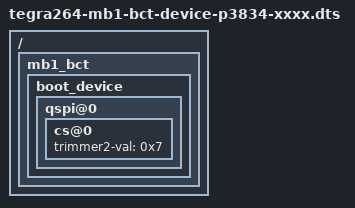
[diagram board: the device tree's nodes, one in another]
/*
 * SPDX-FileCopyrightText: Copyright (c) 2025 NVIDIA CORPORATION & AFFILIATES. All rights reserved.
 * SPDX-License-Identifier: LicenseRef-NvidiaProprietary
 *
 * NVIDIA CORPORATION, its affiliates and licensors retain all intellectual
 * property and proprietary rights in and to this material, related
 * documentation and any modifications thereto. Any use, reproduction,
 * disclosure or distribution of this material and related documentation
 * without an express license agreement from NVIDIA CORPORATION or
 * its affiliates is strictly prohibited.
 */

/dts-v1/;

#include "tegra264-mb1-bct-device-common-l4t.dts"

/ {
	mb1_bct {
		boot_device {
			qspi@0 {
				cs@0 {
					trimmer2-val = <0x7>;
				};
			};
		};
	};
};
